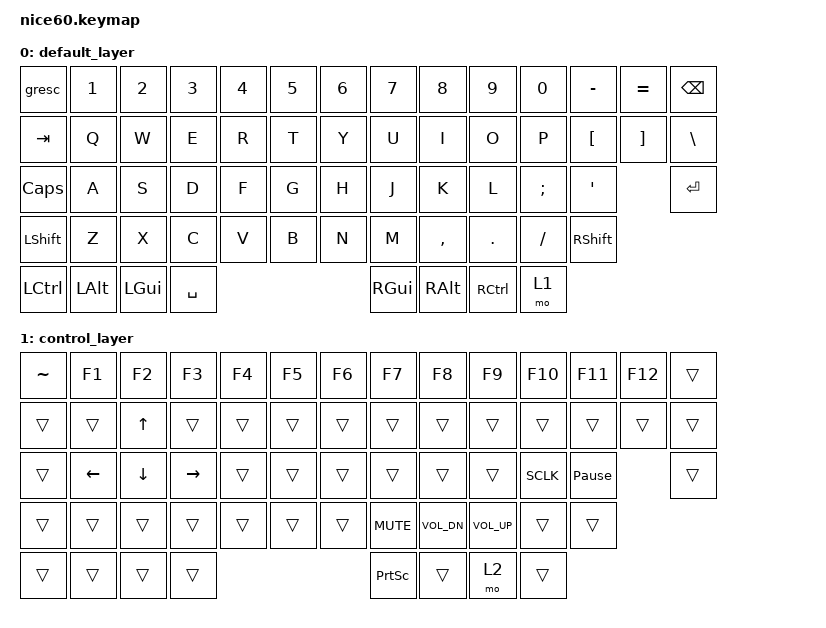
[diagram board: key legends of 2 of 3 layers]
/*
 * Copyright (c) 2021 Nick Winans
 *
 * SPDX-License-Identifier: MIT 2
 */

#include <behaviors.dtsi>
#include <dt-bindings/zmk/keys.h>
#include <dt-bindings/zmk/rgb.h>
#include <dt-bindings/zmk/bt.h>
#include <dt-bindings/zmk/outputs.h>
#include <dt-bindings/zmk/reset.h>
#include <dt-bindings/zmk/ext_power.h>

/ {
    keymap {
        compatible = "zmk,keymap";

        default_layer {
            // ------------------------------------------------------------------------------------------
            // | ESC   |  1    |  2    |  3    |  4    |  5    |  6    |  7    |  8    |  9    |  0    |  -    |  =    |  BKSP   |
            // | TAB   |  Q    |  W    |  E    |  R    |  T    |  Y    |  U    |  I    |  O    |  P    |  [    |  ]    |  \      |
            // | CAPS  |  A    |  S    |  D    |  F    |  G    |  H    |  J    |  K    |  L    |  ;    |  '    |  ENTER       |
            // | SHIFT |  Z    |  X    |  C    |  V    |  B    |  N    |  M    |  ,    |  .    |  /    |  SHIFT         |
            // | CTRL  |  ALT  |  GUI  |           SPACE                 |  ALT  |  GUI  |  RCTRL |             |
            // ------------------------------------------------------------------------------------------
            bindings = <
                &gresc       &kp N1      &kp N2      &kp N3      &kp N4      &kp N5      &kp N6      &kp N7      &kp N8      &kp N9      &kp N0      &kp MINUS   &kp EQUAL   &kp BSPC
                &kp TAB      &kp Q       &kp W       &kp E       &kp R       &kp T       &kp Y       &kp U       &kp I       &kp O       &kp P       &kp LBKT    &kp RBKT    &kp BSLH
                &kp CLCK     &kp A       &kp S       &kp D       &kp F       &kp G       &kp H       &kp J       &kp K       &kp L       &kp SEMI    &kp SQT                  &kp RET
                &kp LSHFT    &kp Z       &kp X       &kp C       &kp V       &kp B       &kp N       &kp M       &kp COMMA   &kp DOT     &kp FSLH    &kp RSHFT
                &kp LCTRL    &kp LALT    &kp LGUI                  &kp SPACE                         &kp RGUI    &kp RALT    &kp RCTRL   &mo 1
            >;
        };

        control_layer {
            // ------------------------------------------------------------------------------------------------
            // | ~     | F1    | F2    | F3    | F4    | F5    | F6    | F7    | F8    | F9    | F10   | F11   | F12   |             |
            // |       |       | UP    |       |       |       |       |       |       |       |       |       |       |             |
            // |       | LEFT  | DOWN  | RIGHT |       |       |       |       |       |       | SCRLK | PAUSE |             |
            // |       |       |       |       |       |       |       | MUTE  | VOL-  | VOL+  |       |       |             |
            // |       |       |       |       |       |       |       |       | PSCRN |       |       |             | MO(2)      |
            // ------------------------------------------------------------------------------------------------
            bindings = <
                &kp TILDE       &kp F1      &kp F2      &kp F3      &kp F4      &kp F5      &kp F6      &kp F7      &kp F8      &kp F9      &kp F10     &kp F11     &kp F12     &trans
                &trans          &trans      &kp UP      &trans      &trans      &trans      &trans      &trans      &trans      &trans      &trans      &trans      &trans      &trans
                &trans          &kp LEFT    &kp DOWN    &kp RIGHT   &trans      &trans      &trans      &trans      &trans      &trans      &kp SCLK   &kp PAUSE_BREAK   &trans
                &trans          &trans      &trans      &trans      &trans      &trans      &trans      &kp C_MUTE  &kp C_VOL_DN &kp C_VOL_UP      &trans      &trans
                &trans          &trans      &trans                &trans                                &kp PSCRN   &trans      &mo 2       &trans                  
            >;
        };

        bt_layer {
            // ------------------------------------------------------------------------------------------------
            // |       | 1      | 2      | 3      | 4      |       |       |       |       |       |       |       |       | BT_CLR |
            // |       |        |        |       |       |       |       |       |       |       |       |       |       |       |
            // |       |        |        |       |       |       |       |       |       |       |       |       |       |       |
            // |       |        |        |       |       |       |       |       |       |       |       |       |       |       |
            // |       |        |        |       |       |       |       |       |       |       |       |       |       |       |
            // ------------------------------------------------------------------------------------------------
            bindings = <
                &trans       &bt BT_SEL 0     &bt BT_SEL 1     &bt BT_SEL 2     &bt BT_SEL 3    &trans     &trans     &trans     &trans     &trans     &trans     &trans     &trans     &bt BT_CLR
                &trans       &trans     &trans     &trans     &trans     &trans     &trans     &trans     &trans     &trans     &trans     &trans     &trans     &trans
                &trans       &trans     &trans     &trans     &trans     &trans     &trans     &trans     &trans     &trans     &trans     &trans     &trans
                &trans       &trans     &trans     &trans     &trans     &trans     &trans     &trans     &trans     &trans     &trans     &trans     &trans
                &trans       &trans     &trans                &trans     &trans     &trans     &trans     &trans
            >;
        };
    };
};
